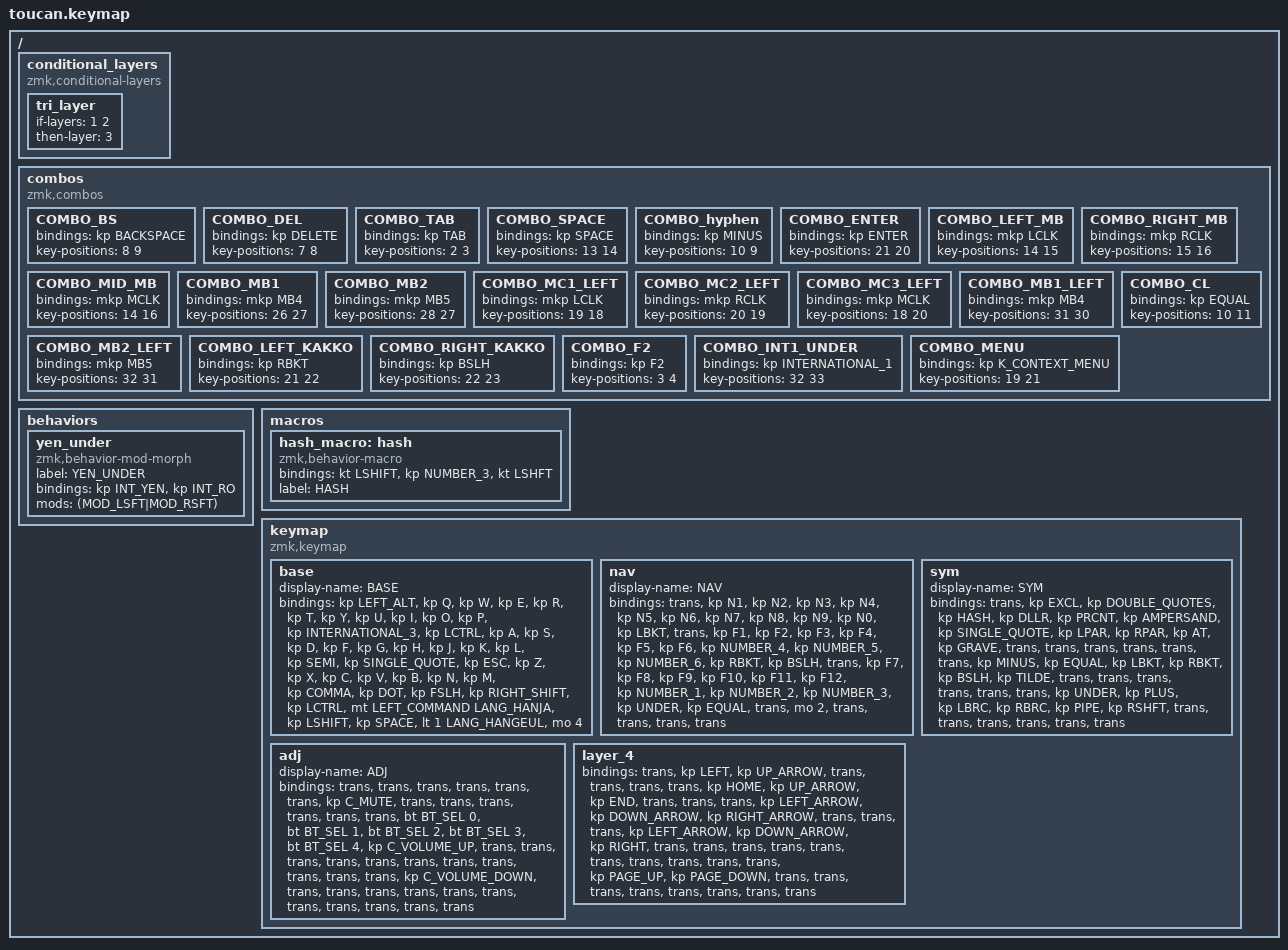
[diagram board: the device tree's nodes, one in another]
#include <behaviors.dtsi>
#include <dt-bindings/zmk/bt.h>
#include <dt-bindings/zmk/keys.h>
#include <dt-bindings/zmk/pointing.h>

#define BASE 0
#define NAV  1
#define SYM  2
#define ADJ  3

/ {
    conditional_layers {
        compatible = "zmk,conditional-layers";

        tri_layer {
            if-layers = <1 2>;
            then-layer = <3>;
        };
    };

    combos {
        compatible = "zmk,combos";

        COMBO_BS {
            bindings = <&kp BACKSPACE>;
            key-positions = <8 9>;
        };

        COMBO_DEL {
            bindings = <&kp DELETE>;
            key-positions = <7 8>;
        };

        COMBO_TAB {
            bindings = <&kp TAB>;
            key-positions = <2 3>;
        };

        COMBO_SPACE {
            bindings = <&kp SPACE>;
            key-positions = <13 14>;
        };

        COMBO_hyphen {
            bindings = <&kp MINUS>;
            key-positions = <10 9>;
        };

        COMBO_ENTER {
            bindings = <&kp ENTER>;
            key-positions = <21 20>;
        };

        COMBO_LEFT_MB {
            bindings = <&mkp LCLK>;
            key-positions = <14 15>;
        };

        COMBO_RIGHT_MB {
            bindings = <&mkp RCLK>;
            key-positions = <15 16>;
        };

        COMBO_MID_MB {
            bindings = <&mkp MCLK>;
            key-positions = <14 16>;
        };

        COMBO_MB1 {
            bindings = <&mkp MB4>;
            key-positions = <26 27>;
        };

        COMBO_MB2 {
            bindings = <&mkp MB5>;
            key-positions = <28 27>;
        };

        COMBO_MC1_LEFT {
            bindings = <&mkp LCLK>;
            key-positions = <19 18>;
        };

        COMBO_MC2_LEFT {
            bindings = <&mkp RCLK>;
            key-positions = <20 19>;
        };

        COMBO_MC3_LEFT {
            bindings = <&mkp MCLK>;
            key-positions = <18 20>;
        };

        COMBO_MB1_LEFT {
            bindings = <&mkp MB4>;
            key-positions = <31 30>;
        };

        COMBO_MB2_LEFT {
            bindings = <&mkp MB5>;
            key-positions = <32 31>;
        };

        COMBO_CL {
            bindings = <&kp EQUAL>;
            key-positions = <10 11>;
        };

        COMBO_LEFT_KAKKO {
            bindings = <&kp RBKT>;
            key-positions = <21 22>;
        };

        COMBO_RIGHT_KAKKO {
            bindings = <&kp BSLH>;
            key-positions = <22 23>;
        };

        COMBO_F2 {
            bindings = <&kp F2>;
            key-positions = <3 4>;
        };

        COMBO_INT1_UNDER {
            bindings = <&kp INTERNATIONAL_1>;
            key-positions = <32 33>;
        };

        COMBO_MENU {
            bindings = <&kp K_CONTEXT_MENU>;
            key-positions = <19 21>;
        };
    };

    behaviors {
        yen_under: yen_under {
            compatible = "zmk,behavior-mod-morph";
            label = "YEN_UNDER";
            bindings = <&kp INT_YEN>, <&kp INT_RO>;

            #binding-cells = <0>;
            mods = <(MOD_LSFT|MOD_RSFT)>;
        };
    };

    macros {
        hash_macro: hash {
            compatible = "zmk,behavior-macro";
            #binding-cells = <0>;
            bindings = <&kt LSHIFT &kp NUMBER_3 &kt LSHFT>;
            label = "HASH";
        };
    };

    keymap {
        compatible = "zmk,keymap";

        base {
            display-name = "BASE";
            bindings = <
&kp LEFT_ALT  &kp Q  &kp W  &kp E  &kp R  &kp T  &kp Y  &kp U  &kp I  &kp O  &kp P  &kp INTERNATIONAL_3  &kp LCTRL  &kp A  &kp S  &kp D  &kp F  &kp G  &kp H  &kp J  &kp K  &kp L  &kp SEMI  &kp SINGLE_QUOTE  &kp ESC  &kp Z  &kp X  &kp C  &kp V  &kp B  &kp N  &kp M  &kp COMMA  &kp DOT  &kp FSLH  &kp RIGHT_SHIFT  &kp LCTRL  &mt LEFT_COMMAND LANG_HANJA  &kp LSHIFT  &kp SPACE  &lt 1 LANG_HANGEUL  &mo 4
            >;
        };

        nav {
            display-name = "NAV";
            bindings = <
&trans  &kp N1  &kp N2  &kp N3  &kp N4  &kp N5  &kp N6  &kp N7  &kp N8  &kp N9  &kp N0  &kp LBKT  &trans  &kp F1  &kp F2  &kp F3  &kp F4  &kp F5  &kp F6  &kp NUMBER_4  &kp NUMBER_5  &kp NUMBER_6  &kp RBKT  &kp BSLH  &trans  &kp F7  &kp F8  &kp F9  &kp F10  &kp F11  &kp F12  &kp NUMBER_1  &kp NUMBER_2  &kp NUMBER_3  &kp UNDER  &kp EQUAL  &trans  &mo 2  &trans  &trans  &trans  &trans
            >;
        };

        sym {
            display-name = "SYM";
            bindings = <
&trans  &kp EXCL  &kp DOUBLE_QUOTES  &kp HASH  &kp DLLR  &kp PRCNT  &kp AMPERSAND  &kp SINGLE_QUOTE  &kp LPAR  &kp RPAR  &kp AT  &kp GRAVE  &trans  &trans  &trans  &trans  &trans  &trans  &kp MINUS  &kp EQUAL  &kp LBKT  &kp RBKT  &kp BSLH  &kp TILDE  &trans  &trans  &trans  &trans  &trans  &trans  &kp UNDER  &kp PLUS  &kp LBRC  &kp RBRC  &kp PIPE  &kp RSHFT  &trans  &trans  &trans  &trans  &trans  &trans
            >;
        };

        adj {
            display-name = "ADJ";
            bindings = <
&trans  &trans  &trans  &trans  &trans  &trans  &kp C_MUTE  &trans  &trans  &trans  &trans  &trans  &trans  &bt BT_SEL 0  &bt BT_SEL 1  &bt BT_SEL 2  &bt BT_SEL 3  &bt BT_SEL 4  &kp C_VOLUME_UP  &trans  &trans  &trans  &trans  &trans  &trans  &trans  &trans  &trans  &trans  &trans  &kp C_VOLUME_DOWN  &trans  &trans  &trans  &trans  &trans  &trans  &trans  &trans  &trans  &trans  &trans
            >;
        };

        layer_4 {
            bindings = <
&trans  &kp LEFT  &kp UP_ARROW  &trans  &trans  &trans  &trans  &kp HOME  &kp UP_ARROW  &kp END  &trans  &trans  &trans  &kp LEFT_ARROW  &kp DOWN_ARROW  &kp RIGHT_ARROW  &trans  &trans  &trans  &kp LEFT_ARROW  &kp DOWN_ARROW  &kp RIGHT  &trans  &trans  &trans  &trans  &trans  &trans  &trans  &trans  &trans  &trans  &kp PAGE_UP  &kp PAGE_DOWN  &trans  &trans  &trans  &trans  &trans  &trans  &trans  &trans
            >;
        };
    };
};
